# DSS_EDP0_MHDPTX_WRAPPER_ECC_AGGR_PHY_CFG register map
Vendor: Texas Instruments
Peripheral module from a debugger description file (folder J7ES).
Registers are 32-bit, access not given, reset 0x0 unless marked. A register's access mark holds for its fields unless they carry their own. Offsets are as the file gives them; lines under a group give offsets from that group; [hi:lo] are bit positions; {n}, {i} and the like mark numbered series; 'fields as' and 'values as' point back to an identical list; <NAME> marks a mode.

## DSS_EDP0_MHDPTX_WRAPPER_ECC_AGGR_PHY_CFG
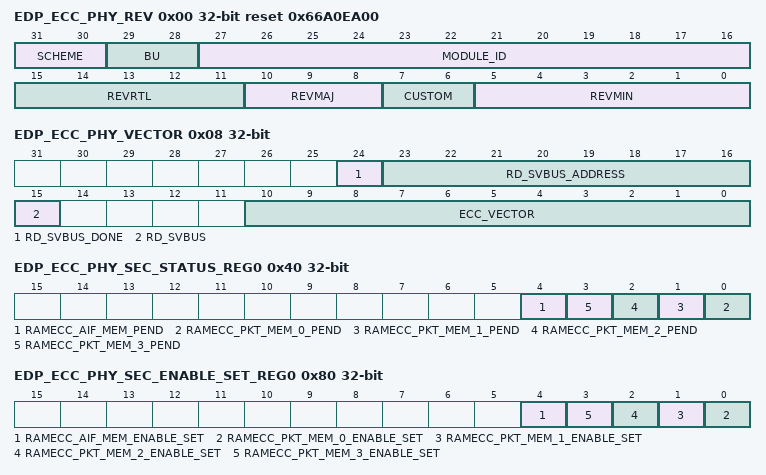
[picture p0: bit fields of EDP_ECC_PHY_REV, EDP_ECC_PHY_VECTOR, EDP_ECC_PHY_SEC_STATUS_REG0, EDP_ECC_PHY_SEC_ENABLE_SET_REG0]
0x00 EDP_ECC_PHY_REV ro reset 0x66A0EA00 — Revision parameters
  [31:30] SCHEME
  [29:28] BU
  [27:16] MODULE_ID
  [15:11] REVRTL — RTL version
  [10:8] REVMAJ — Major version
  [7:6] CUSTOM — Custom version
  [5:0] REVMIN — Minor version
0x08 EDP_ECC_PHY_VECTOR — ECC Register
  [24] RD_SVBUS_DONE — Status to indicate if read on serial VBUS is complete, write of any value will clear this bit. (access RW1C)
  [23:16] RD_SVBUS_ADDRESS rw — Read address
  [15] RD_SVBUS — Write 1 to trigger a read on the serial VBUS (access RW1S)
  [10:0] ECC_VECTOR rw — Value written to select the corresponding ECC RAM for control or status
0x0C EDP_ECC_PHY_STAT ro reset 0x5 — Misc Status
  [10:0] NUM_RAMS — Indicates the number of RAMS serviced by the ECC aggregator
0x10 EDP_ECC_PHY_RESERVED_SVBUS_y rw — Reference other documents that contain the ECC RAM wrapper and EDC controller serial vbus register sets. Offset = 1010h + (y * 4h); where y = 0h to 7h
  [31:0] DATA — Serial VBUS register data
0x3C EDP_ECC_PHY_SEC_EOI_REG — EOI Register The EOI register is used to re-trigger the pulse interrupt signal to ensure that any nested interrupt events are serviced. The software interrupt handler must write to the EOI register at the end of the current interrupt processing routine, so that new events can re-trigger the pulse interrupt signal again. For level interrupt signals the EOI register is not functional and must not be used.
  [0] EOI_WR — EOI Register (access RW1S)
0x40 EDP_ECC_PHY_SEC_STATUS_REG0 — Interrupt Status Register 0
  [4] RAMECC_AIF_MEM_PEND — Interrupt Pending Status for ramecc_aif_mem_pend (access RW1S)
  [n] RAMECC_PKT_MEM_{n}_PEND (n=0..3) — Interrupt Pending Status for ramecc_pkt_mem_{n}_pend (access RW1S)
0x80 EDP_ECC_PHY_SEC_ENABLE_SET_REG0 — Interrupt Enable Set Register 0
  [4] RAMECC_AIF_MEM_ENABLE_SET — Interrupt Enable Set Register for ramecc_aif_mem_pend (access RW1S)
  [n] RAMECC_PKT_MEM_{n}_ENABLE_SET (n=0..3) — Interrupt Enable Set Register for ramecc_pkt_mem_{n}_pend (access RW1S)
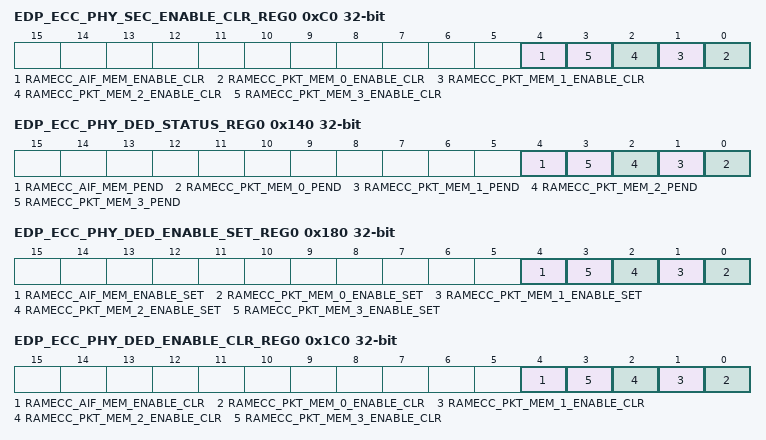
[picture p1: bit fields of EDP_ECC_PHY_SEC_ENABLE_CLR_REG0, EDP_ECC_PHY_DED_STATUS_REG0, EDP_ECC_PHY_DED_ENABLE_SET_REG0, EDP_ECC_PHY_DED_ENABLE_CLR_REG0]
0xC0 EDP_ECC_PHY_SEC_ENABLE_CLR_REG0 — Interrupt Enable Clear Register 0
  [4] RAMECC_AIF_MEM_ENABLE_CLR — Interrupt Enable Clear Register for ramecc_aif_mem_pend (access RW1C)
  [n] RAMECC_PKT_MEM_{n}_ENABLE_CLR (n=0..3) — Interrupt Enable Clear Register for ramecc_pkt_mem_{n}_pend (access RW1C)
0x13C EDP_ECC_PHY_DED_EOI_REG — EOI Register The EOI register is used to re-trigger the pulse interrupt signal to ensure that any nested interrupt events are serviced. The software interrupt handler must write to the EOI register at the end of the current interrupt processing routine, so that new events can re-trigger the pulse interrupt signal again. For level interrupt signals the EOI register is not functional and must not be used.
  [0] EOI_WR — EOI Register (access RW1S)
0x140 EDP_ECC_PHY_DED_STATUS_REG0 — Interrupt Status Register 0
  fields as EDP_ECC_PHY_SEC_STATUS_REG0
0x180 EDP_ECC_PHY_DED_ENABLE_SET_REG0 — Interrupt Enable Set Register 0
  fields as EDP_ECC_PHY_SEC_ENABLE_SET_REG0
0x1C0 EDP_ECC_PHY_DED_ENABLE_CLR_REG0 — Interrupt Enable Clear Register 0
  fields as EDP_ECC_PHY_SEC_ENABLE_CLR_REG0
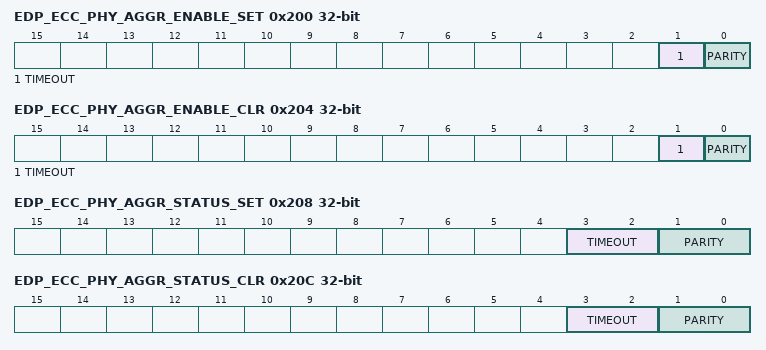
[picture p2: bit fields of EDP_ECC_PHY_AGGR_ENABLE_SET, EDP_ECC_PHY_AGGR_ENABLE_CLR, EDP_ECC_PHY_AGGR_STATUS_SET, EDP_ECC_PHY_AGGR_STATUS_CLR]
0x200 EDP_ECC_PHY_AGGR_ENABLE_SET — AGGR interrupt enable set Register
  [1] TIMEOUT — interrupt enable set for svbus timeout errors (access RW1S)
  [0] PARITY — interrupt enable set for parity errors (access RW1S)
0x204 EDP_ECC_PHY_AGGR_ENABLE_CLR — AGGR interrupt enable clear Register
  [1] TIMEOUT — interrupt enable clear for svbus timeout errors (access RW1C)
  [0] PARITY — interrupt enable clear for parity errors (access RW1C)
0x208 EDP_ECC_PHY_AGGR_STATUS_SET — AGGR interrupt status set Register
  [3:2] TIMEOUT — interrupt status set for svbus timeout errors (access RWincr)
  [1:0] PARITY — interrupt status set for parity errors (access RWincr)
0x20C EDP_ECC_PHY_AGGR_STATUS_CLR — AGGR interrupt status clear Register
  [3:2] TIMEOUT — interrupt status clear for svbus timeout errors (access RWdecr)
  [1:0] PARITY — interrupt status clear for parity errors (access RWdecr)
